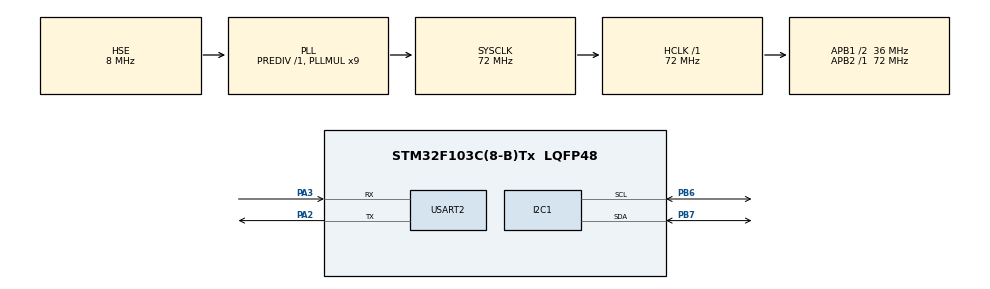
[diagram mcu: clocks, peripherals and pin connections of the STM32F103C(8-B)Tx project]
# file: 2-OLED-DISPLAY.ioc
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I2C1.I2C_Mode=I2C_Fast
Mcu.Family=STM32F1
Mcu.Name=STM32F103C(8-B)Tx
Mcu.Package=LQFP48
NVIC.PriorityGroup=NVIC_PRIORITYGROUP_4
PA13.Mode=Serial_Wire
PA13.Signal=SYS_JTMS-SWDIO
PA14.Mode=Serial_Wire
PA14.Signal=SYS_JTCK-SWCLK
PA2.Mode=Asynchronous
PA2.Signal=USART2_TX
PA3.Mode=Asynchronous
PA3.Signal=USART2_RX
PB6.Mode=I2C
PB6.Signal=I2C1_SCL
PB7.Mode=I2C
PB7.Signal=I2C1_SDA
PD0-OSC_IN.Mode=HSE-External-Oscillator
PD0-OSC_IN.Signal=RCC_OSC_IN
PD1-OSC_OUT.Mode=HSE-External-Oscillator
PD1-OSC_OUT.Signal=RCC_OSC_OUT
ProjectManager.HeapSize=0x200
ProjectManager.StackSize=0x400
ProjectManager.TargetToolchain=STM32CubeIDE
RCC.AHBFreq_Value=72000000
RCC.APB1CLKDivider=RCC_HCLK_DIV2
RCC.APB1Freq_Value=36000000
RCC.APB1TimFreq_Value=72000000
RCC.APB2Freq_Value=72000000
RCC.APB2TimFreq_Value=72000000
RCC.HCLKFreq_Value=72000000
RCC.PLLMUL=RCC_PLL_MUL9
RCC.PLLSourceVirtual=RCC_PLLSOURCE_HSE
RCC.SYSCLKFreq_VALUE=72000000
RCC.SYSCLKSource=RCC_SYSCLKSOURCE_PLLCLK
RCC.USBFreq_Value=72000000
USART2.VirtualMode=VM_ASYNC
board=custom

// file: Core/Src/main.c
/* USER CODE BEGIN Header */
/**
  ******************************************************************************
  * @file           : main.c
  * @brief          : Main program body
  ******************************************************************************
  * @attention
  *
  * Copyright (c) 2023 STMicroelectronics.
  * All rights reserved.
  *
  * This software is licensed under terms that can be found in the LICENSE file
  * in the root directory of this software component.
  * If no LICENSE file comes with this software, it is provided AS-IS.
  *
  ******************************************************************************
  */
/* USER CODE END Header */
#include "main.h"
#include "ssd1306.h"
#include "fonts.h"
#include "bitmap.h"
#include "test.h"

/* USER CODE BEGIN Includes */
#define delay HAL_MAX_DELAY
//#define uart_rcv HAL_UART_Receive
/* USER CODE END Includes */

I2C_HandleTypeDef hi2c1;

UART_HandleTypeDef huart2;

GPIO_InitTypeDef GPIO_InitStruct;

void SystemClock_Config(void);
static void MX_GPIO_Init(void);
static void MX_I2C1_Init(void);
static void MX_USART2_UART_Init(void);
//void HAL_UART_MspInit(UART_HandleTypeDef*);

int main(void)
{

  /* MCU Configuration--------------------------------------------------------*/

  /* Reset of all peripherals, Initializes the Flash interface and the Systick. */
  HAL_Init();

  /* Configure the system clock */
  SystemClock_Config();

  /* Initialize all configured peripherals */

  MX_GPIO_Init();
  MX_I2C1_Init();
  MX_USART2_UART_Init();

  /* USER CODE BEGIN 2 */

  SSD1306_Init();

  /* USER CODE END 2 */

  uint8_t Data;
  //char buff[100];

  //uart_rcv(&huart2, &Data, 1, delay);

  uint8_t set[16] = {'\0'};

  /* Infinite loop */
  /* USER CODE BEGIN WHILE */
  while (1)
  {
	  HAL_UART_Receive(&huart2, &set, 6, delay);

	  	  //strncpy(set,(char *)Data,strlen(Data));
	  	  /* USER CODE END WHILE */
		  // if(Data == 0xAA)
	  if(1)
	  {
		 SSD1306_GotoXY (0, 0);
		 SSD1306_Puts( set, &Font_11x18, 1);
		 SSD1306_UpdateScreen();

		 //SSD1306_Clear();
		 //SSD1306_GotoXY (0,  0);
		 //SSD1306_Puts ( &buff   , &Font_11x18, 1);
		 //SSD1306_GotoXY (0, 0);
		 //SSD1306_Puts (" INTENT ", &Font_11x18, 1);
		 //SSD1306_GotoXY (10, 30);
		 //SSD1306_Puts (" DESIGN ", &Font_11x18, 1);
		 //SSD1306_UpdateScreen(); //display
		 //HAL_Delay (2000);
		 //SSD1306_ScrollRight(0X00, 0X0F);
		 HAL_UART_Transmit(&huart2, &Data, 1, delay);
	  }
	   //HAL_Delay(4000);
	   //SSD1306_ScrollLeft(0X00, 0X0F);
	   //HAL_Delay(4000);
	  if(Data == 0xAB )
	  {
		  HAL_UART_Transmit(&huart2, &Data, 1, delay);
		  SSD1306_GotoXY (0,0);
		  SSD1306_Puts ("PRIVATE", &Font_11x18, 1);
		  SSD1306_GotoXY (10, 30);
		  SSD1306_Puts (" LIMITED ", &Font_11x18, 1);
		  SSD1306_UpdateScreen(); //display
		  HAL_Delay (2000);
		  SSD1306_ScrollRight(0X00, 0X0F);

	  }
	  if(Data == 0xAC)
	  {
		  HAL_UART_Transmit(&huart2, &Data, 1, delay);
		  SSD1306_Clear();
	      SSD1306_DrawBitmap(0, 0, logo, 128, 50, 1);
	      SSD1306_UpdateScreen();
	      //HAL_Delay(2000);
	      SSD1306_ScrollRight(0X00, 0X0F);
	      //HAL_Delay(9500);
	      //SSD1306_ScrollLeft(0X00, 0X0F);
	  	  //HAL_Delay(4000);
	      //SSD1306_ScrollRight(0X00, 0X0F);
	      //HAL_Delay(4000);
	      //SSD1306_ScrollLeft(0X00, 0X0F);
	      //HAL_Delay(4000);*/
	  }
	  if(Data == 0xAD)
	  {
		  HAL_UART_Transmit(&huart2, &Data, 2, delay);
	  	  SSD1306_Stopscroll();
	  }

	  if(Data == 0xBA)
	  {
		  HAL_UART_Transmit(&huart2, &Data, 2, delay);
		  SSD1306_Clear();
		  SSD1306_InvertDisplay(1);
		  HAL_Delay(1000);
		  SSD1306_InvertDisplay(0);
		  //HAL_Delay(1000);
	  	       }
	  if(Data == 0xBB)
	  {
		  HAL_UART_Transmit(&huart2, &Data, 2, delay);
	  	  SSD1306_Clear();
	  }
  }
}

void SystemClock_Config(void)
{
  RCC_OscInitTypeDef RCC_OscInitStruct = {0};
  RCC_ClkInitTypeDef RCC_ClkInitStruct = {0};

  /** Initializes the RCC Oscillators according to the specified parameters
  * in the RCC_OscInitTypeDef structure.
  */
  RCC_OscInitStruct.OscillatorType = RCC_OSCILLATORTYPE_HSE;
  RCC_OscInitStruct.HSEState = RCC_HSE_ON;
  RCC_OscInitStruct.HSEPredivValue = RCC_HSE_PREDIV_DIV1;
  RCC_OscInitStruct.HSIState = RCC_HSI_ON;
  RCC_OscInitStruct.PLL.PLLState = RCC_PLL_ON;
  RCC_OscInitStruct.PLL.PLLSource = RCC_PLLSOURCE_HSE;
  RCC_OscInitStruct.PLL.PLLMUL = RCC_PLL_MUL9;
  if (HAL_RCC_OscConfig(&RCC_OscInitStruct) != HAL_OK)
  {
    Error_Handler();
  }

  /** Initializes the CPU, AHB and APB buses clocks
  */
  RCC_ClkInitStruct.ClockType = RCC_CLOCKTYPE_HCLK|RCC_CLOCKTYPE_SYSCLK
                              |RCC_CLOCKTYPE_PCLK1|RCC_CLOCKTYPE_PCLK2;
  RCC_ClkInitStruct.SYSCLKSource = RCC_SYSCLKSOURCE_PLLCLK;
  RCC_ClkInitStruct.AHBCLKDivider = RCC_SYSCLK_DIV1;
  RCC_ClkInitStruct.APB1CLKDivider = RCC_HCLK_DIV2;
  RCC_ClkInitStruct.APB2CLKDivider = RCC_HCLK_DIV1;

  if (HAL_RCC_ClockConfig(&RCC_ClkInitStruct, FLASH_LATENCY_2) != HAL_OK)
  {
    Error_Handler();
  }
}

static void MX_I2C1_Init(void)
{

  hi2c1.Instance = I2C1;
  hi2c1.Init.ClockSpeed = 400000;
  hi2c1.Init.DutyCycle = I2C_DUTYCYCLE_2;
  hi2c1.Init.OwnAddress1 = 0;
  hi2c1.Init.AddressingMode = I2C_ADDRESSINGMODE_7BIT;
  hi2c1.Init.DualAddressMode = I2C_DUALADDRESS_DISABLE;
  hi2c1.Init.OwnAddress2 = 0;
  hi2c1.Init.GeneralCallMode = I2C_GENERALCALL_DISABLE;
  hi2c1.Init.NoStretchMode = I2C_NOSTRETCH_DISABLE;
  if (HAL_I2C_Init(&hi2c1) != HAL_OK)
  {
    Error_Handler();
  }

}

static void MX_USART2_UART_Init(void)
{

  huart2.Instance = USART2;
  huart2.Init.BaudRate = 115200;
  huart2.Init.WordLength = UART_WORDLENGTH_8B;
  huart2.Init.StopBits = UART_STOPBITS_1;
  huart2.Init.Parity = UART_PARITY_NONE;
  huart2.Init.Mode = UART_MODE_TX_RX;
  huart2.Init.HwFlowCtl = UART_HWCONTROL_NONE;
  huart2.Init.OverSampling = UART_OVERSAMPLING_16;
  if (HAL_UART_Init(&huart2) != HAL_OK)
  {
    Error_Handler();
  }

}

static void MX_GPIO_Init(void)
{

  /* GPIO Ports Clock Enable */
  __HAL_RCC_GPIOD_CLK_ENABLE();
  __HAL_RCC_GPIOA_CLK_ENABLE();
  __HAL_RCC_GPIOB_CLK_ENABLE();

}

/*void HAL_UART_RxCpltCallback(UART_HandleTypeDef *huart)
{
  if (huart == &huart1) // check if the interrupt came from UART1
  {
    if (uart_rx_len < sizeof(uart_rx_buf)) // check if there is room in the buffer
    {
      uart_rx_buf[uart_rx_len++] = huart1.Instance->DR; // read the received byte and store it in the buffer
    }
  }
}*/

void Error_Handler(void)
{
  __disable_irq();
  while (1)
  {
  }
}
